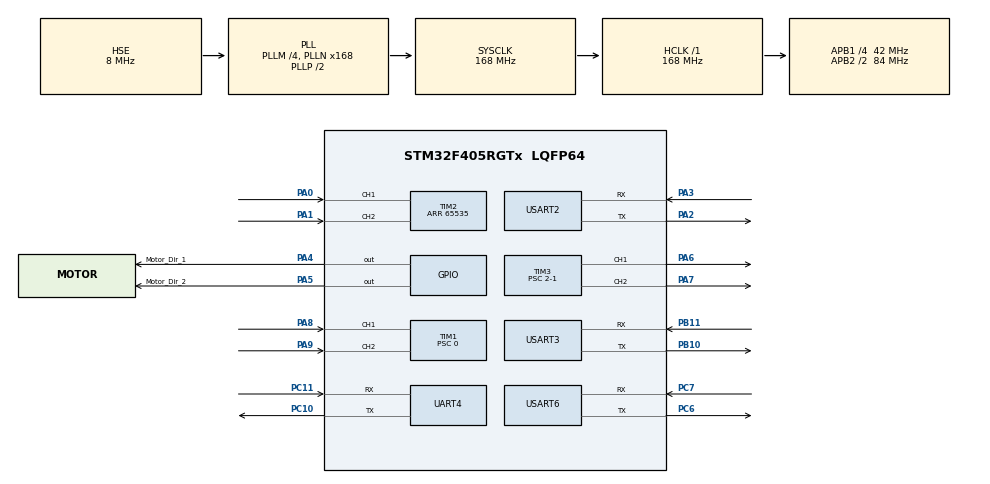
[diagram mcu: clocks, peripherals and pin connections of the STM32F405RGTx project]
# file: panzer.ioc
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Dma.Request0=USART3_RX
Dma.Request1=USART6_TX
Dma.Request2=USART6_RX
Dma.Request3=UART4_RX
Dma.Request4=UART4_TX
Dma.Request5=USART3_TX
Dma.Request6=USART2_RX
Dma.Request7=USART2_TX
Dma.UART4_RX.3.Direction=DMA_PERIPH_TO_MEMORY
Dma.UART4_RX.3.FIFOMode=DMA_FIFOMODE_DISABLE
Dma.UART4_RX.3.Instance=DMA1_Stream2
Dma.UART4_RX.3.MemDataAlignment=DMA_MDATAALIGN_BYTE
Dma.UART4_RX.3.MemInc=DMA_MINC_ENABLE
Dma.UART4_RX.3.Mode=DMA_CIRCULAR
Dma.UART4_RX.3.PeriphDataAlignment=DMA_PDATAALIGN_BYTE
Dma.UART4_RX.3.PeriphInc=DMA_PINC_DISABLE
Dma.UART4_RX.3.Priority=DMA_PRIORITY_LOW
Dma.UART4_TX.4.Direction=DMA_MEMORY_TO_PERIPH
Dma.UART4_TX.4.FIFOMode=DMA_FIFOMODE_DISABLE
Dma.UART4_TX.4.Instance=DMA1_Stream4
Dma.UART4_TX.4.MemDataAlignment=DMA_MDATAALIGN_BYTE
Dma.UART4_TX.4.MemInc=DMA_MINC_ENABLE
Dma.UART4_TX.4.Mode=DMA_NORMAL
Dma.UART4_TX.4.PeriphDataAlignment=DMA_PDATAALIGN_BYTE
Dma.UART4_TX.4.PeriphInc=DMA_PINC_DISABLE
Dma.UART4_TX.4.Priority=DMA_PRIORITY_LOW
Dma.USART2_RX.6.Direction=DMA_PERIPH_TO_MEMORY
Dma.USART2_RX.6.FIFOMode=DMA_FIFOMODE_DISABLE
Dma.USART2_RX.6.Instance=DMA1_Stream5
Dma.USART2_RX.6.MemDataAlignment=DMA_MDATAALIGN_BYTE
Dma.USART2_RX.6.MemInc=DMA_MINC_ENABLE
Dma.USART2_RX.6.Mode=DMA_CIRCULAR
Dma.USART2_RX.6.PeriphDataAlignment=DMA_PDATAALIGN_BYTE
Dma.USART2_RX.6.PeriphInc=DMA_PINC_DISABLE
Dma.USART2_RX.6.Priority=DMA_PRIORITY_LOW
Dma.USART2_TX.7.Direction=DMA_MEMORY_TO_PERIPH
Dma.USART2_TX.7.FIFOMode=DMA_FIFOMODE_DISABLE
Dma.USART2_TX.7.Instance=DMA1_Stream6
Dma.USART2_TX.7.MemDataAlignment=DMA_MDATAALIGN_BYTE
Dma.USART2_TX.7.MemInc=DMA_MINC_ENABLE
Dma.USART2_TX.7.Mode=DMA_NORMAL
Dma.USART2_TX.7.PeriphDataAlignment=DMA_PDATAALIGN_BYTE
Dma.USART2_TX.7.PeriphInc=DMA_PINC_DISABLE
Dma.USART2_TX.7.Priority=DMA_PRIORITY_LOW
Dma.USART3_RX.0.Direction=DMA_PERIPH_TO_MEMORY
Dma.USART3_RX.0.FIFOMode=DMA_FIFOMODE_DISABLE
Dma.USART3_RX.0.Instance=DMA1_Stream1
Dma.USART3_RX.0.MemDataAlignment=DMA_MDATAALIGN_BYTE
Dma.USART3_RX.0.MemInc=DMA_MINC_ENABLE
Dma.USART3_RX.0.Mode=DMA_CIRCULAR
Dma.USART3_RX.0.PeriphDataAlignment=DMA_PDATAALIGN_BYTE
Dma.USART3_RX.0.PeriphInc=DMA_PINC_DISABLE
Dma.USART3_RX.0.Priority=DMA_PRIORITY_LOW
Dma.USART3_TX.5.Direction=DMA_MEMORY_TO_PERIPH
Dma.USART3_TX.5.FIFOMode=DMA_FIFOMODE_DISABLE
Dma.USART3_TX.5.Instance=DMA1_Stream3
Dma.USART3_TX.5.MemDataAlignment=DMA_MDATAALIGN_BYTE
Dma.USART3_TX.5.MemInc=DMA_MINC_ENABLE
Dma.USART3_TX.5.Mode=DMA_NORMAL
Dma.USART3_TX.5.PeriphDataAlignment=DMA_PDATAALIGN_BYTE
Dma.USART3_TX.5.PeriphInc=DMA_PINC_DISABLE
Dma.USART3_TX.5.Priority=DMA_PRIORITY_LOW
Dma.USART6_RX.2.Direction=DMA_PERIPH_TO_MEMORY
Dma.USART6_RX.2.FIFOMode=DMA_FIFOMODE_DISABLE
Dma.USART6_RX.2.Instance=DMA2_Stream1
Dma.USART6_RX.2.MemDataAlignment=DMA_MDATAALIGN_BYTE
Dma.USART6_RX.2.MemInc=DMA_MINC_ENABLE
Dma.USART6_RX.2.Mode=DMA_CIRCULAR
Dma.USART6_RX.2.PeriphDataAlignment=DMA_PDATAALIGN_BYTE
Dma.USART6_RX.2.PeriphInc=DMA_PINC_DISABLE
Dma.USART6_RX.2.Priority=DMA_PRIORITY_LOW
Dma.USART6_TX.1.Direction=DMA_MEMORY_TO_PERIPH
Dma.USART6_TX.1.FIFOMode=DMA_FIFOMODE_DISABLE
Dma.USART6_TX.1.Instance=DMA2_Stream6
Dma.USART6_TX.1.MemDataAlignment=DMA_MDATAALIGN_BYTE
Dma.USART6_TX.1.MemInc=DMA_MINC_ENABLE
Dma.USART6_TX.1.Mode=DMA_NORMAL
Dma.USART6_TX.1.PeriphDataAlignment=DMA_PDATAALIGN_BYTE
Dma.USART6_TX.1.PeriphInc=DMA_PINC_DISABLE
Dma.USART6_TX.1.Priority=DMA_PRIORITY_LOW
Mcu.Family=STM32F4
Mcu.Name=STM32F405RGTx
Mcu.Package=LQFP64
NVIC.DMA1_Stream1_IRQn=true\:0\:0\:false\:false\:true\:false\:true\:true
NVIC.DMA1_Stream2_IRQn=true\:0\:0\:false\:false\:true\:false\:true\:true
NVIC.DMA1_Stream3_IRQn=true\:0\:0\:false\:false\:true\:false\:true\:true
NVIC.DMA1_Stream4_IRQn=true\:0\:0\:false\:false\:true\:false\:true\:true
NVIC.DMA1_Stream5_IRQn=true\:0\:0\:false\:false\:true\:false\:true\:true
NVIC.DMA1_Stream6_IRQn=true\:0\:0\:false\:false\:true\:false\:true\:true
NVIC.DMA2_Stream1_IRQn=true\:0\:0\:false\:false\:true\:false\:true\:true
NVIC.DMA2_Stream6_IRQn=true\:0\:0\:false\:false\:true\:false\:true\:true
NVIC.PriorityGroup=NVIC_PRIORITYGROUP_4
NVIC.TIM4_IRQn=true\:1\:0\:true\:false\:true\:true\:true\:true
NVIC.TIM5_IRQn=true\:2\:0\:true\:false\:true\:true\:true\:true
NVIC.UART4_IRQn=true\:0\:0\:true\:false\:true\:true\:true\:true
NVIC.USART2_IRQn=true\:0\:0\:true\:false\:true\:true\:true\:true
NVIC.USART3_IRQn=true\:0\:0\:false\:false\:true\:true\:true\:true
NVIC.USART6_IRQn=true\:0\:0\:true\:false\:true\:true\:true\:true
PA0-WKUP.GPIO_Speed=GPIO_SPEED_FREQ_VERY_HIGH
PA0-WKUP.Signal=S_TIM2_CH1_ETR
PA1.GPIO_Speed=GPIO_SPEED_FREQ_VERY_HIGH
PA1.Signal=S_TIM2_CH2
PA13.Mode=Serial_Wire
PA13.Signal=SYS_JTMS-SWDIO
PA14.Mode=Serial_Wire
PA14.Signal=SYS_JTCK-SWCLK
PA2.Mode=Asynchronous
PA2.Signal=USART2_TX
PA3.Mode=Asynchronous
PA3.Signal=USART2_RX
PA4.GPIO_Label=Motor_Dir_1
PA4.GPIO_PuPd=GPIO_PULLUP
PA4.PinState=GPIO_PIN_SET
PA4.Signal=GPIO_Output
PA5.GPIO_Label=Motor_Dir_2
PA5.GPIO_PuPd=GPIO_PULLUP
PA5.PinState=GPIO_PIN_SET
PA5.Signal=GPIO_Output
PA6.GPIO_Speed=GPIO_SPEED_FREQ_HIGH
PA6.Signal=S_TIM3_CH1
PA7.GPIO_Speed=GPIO_SPEED_FREQ_HIGH
PA7.Signal=S_TIM3_CH2
PA8.GPIO_PuPd=GPIO_PULLUP
PA8.GPIO_Speed=GPIO_SPEED_FREQ_VERY_HIGH
PA8.Signal=S_TIM1_CH1
PA9.GPIO_PuPd=GPIO_PULLUP
PA9.GPIO_Speed=GPIO_SPEED_FREQ_VERY_HIGH
PA9.Signal=S_TIM1_CH2
PB10.Mode=Asynchronous
PB10.Signal=USART3_TX
PB11.Mode=Asynchronous
PB11.Signal=USART3_RX
PC10.Mode=Asynchronous
PC10.Signal=UART4_TX
PC11.Mode=Asynchronous
PC11.Signal=UART4_RX
PC6.Mode=Asynchronous
PC6.Signal=USART6_TX
PC7.Mode=Asynchronous
PC7.Signal=USART6_RX
PH0-OSC_IN.Mode=HSE-External-Oscillator
PH0-OSC_IN.Signal=RCC_OSC_IN
PH1-OSC_OUT.Mode=HSE-External-Oscillator
PH1-OSC_OUT.Signal=RCC_OSC_OUT
ProjectManager.HeapSize=0x200
ProjectManager.StackSize=0x400
ProjectManager.TargetToolchain=MDK-ARM V5.32
RCC.48MHZClocksFreq_Value=84000000
RCC.AHBFreq_Value=168000000
RCC.APB1CLKDivider=RCC_HCLK_DIV4
RCC.APB1Freq_Value=42000000
RCC.APB1TimFreq_Value=84000000
RCC.APB2CLKDivider=RCC_HCLK_DIV2
RCC.APB2Freq_Value=84000000
RCC.APB2TimFreq_Value=168000000
RCC.CortexFreq_Value=168000000
RCC.HCLKFreq_Value=168000000
RCC.HSE_VALUE=8000000
RCC.HSI_VALUE=16000000
RCC.LSE_VALUE=32768
RCC.PLLM=4
RCC.PLLN=168
RCC.PLLSourceVirtual=RCC_PLLSOURCE_HSE
RCC.SYSCLKFreq_VALUE=168000000
RCC.SYSCLKSource=RCC_SYSCLKSOURCE_PLLCLK
RCC.VCOOutputFreq_Value=336000000
SH.S_TIM1_CH1.0=TIM1_CH1,Encoder_Interface
SH.S_TIM1_CH2.0=TIM1_CH2,Encoder_Interface
SH.S_TIM2_CH1_ETR.0=TIM2_CH1,Encoder_Interface
SH.S_TIM2_CH2.0=TIM2_CH2,Encoder_Interface
SH.S_TIM3_CH1.0=TIM3_CH1,PWM Generation1 CH1
SH.S_TIM3_CH2.0=TIM3_CH2,PWM Generation2 CH2
TIM1.AutoReloadPreload=TIM_AUTORELOAD_PRELOAD_ENABLE
TIM1.EncoderMode=TIM_ENCODERMODE_TI12
TIM1.Prescaler=0
TIM2.AutoReloadPreload=TIM_AUTORELOAD_PRELOAD_ENABLE
TIM2.EncoderMode=TIM_ENCODERMODE_TI12
TIM2.Period=65535
TIM3.AutoReloadPreload=TIM_AUTORELOAD_PRELOAD_ENABLE
TIM3.Channel-PWM\ Generation1\ CH1=TIM_CHANNEL_1
TIM3.Channel-PWM\ Generation2\ CH2=TIM_CHANNEL_2
TIM3.OCMode_PWM-PWM\ Generation1\ CH1=TIM_OCMODE_PWM2
TIM3.OCMode_PWM-PWM\ Generation2\ CH2=TIM_OCMODE_PWM2
TIM3.Period=1680-1
TIM3.Prescaler=2-1
TIM3.Pulse-PWM\ Generation1\ CH1=0
TIM3.Pulse-PWM\ Generation2\ CH2=0
TIM4.AutoReloadPreload=TIM_AUTORELOAD_PRELOAD_ENABLE
TIM4.Period=1000-1
TIM4.Prescaler=840-1
TIM5.AutoReloadPreload=TIM_AUTORELOAD_PRELOAD_ENABLE
TIM5.Period=10000-1
TIM5.Prescaler=840-1
UART4.VirtualMode=Asynchronous
USART2.VirtualMode=VM_ASYNC
USART3.VirtualMode=VM_ASYNC
USART6.VirtualMode=VM_ASYNC
VP_TIM3_VS_ClockSourceINT.Mode=Internal
VP_TIM4_VS_ClockSourceINT.Mode=Internal
VP_TIM5_VS_ClockSourceINT.Mode=Internal
board=custom

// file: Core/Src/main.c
/* USER CODE BEGIN Header */
/**
 ******************************************************************************
 * @file           : main.c
 * @brief          : Main program body
 ******************************************************************************
 * @attention
 *
 * Copyright (c) 2025 STMicroelectronics.
 * All rights reserved.
 *
 * This software is licensed under terms that can be found in the LICENSE file
 * in the root directory of this software component.
 * If no LICENSE file comes with this software, it is provided AS-IS.
 *
 ******************************************************************************
 */
/* USER CODE END Header */
#include "main.h"
#include "dma.h"
#include "tim.h"
#include "usart.h"
#include "gpio.h"

/* USER CODE BEGIN Includes */
#include "Encode.h"
#include "interurp.h"
#include "Bule_Tooch.h"
#include "stdint.h"

/* USER CODE END Includes */

void SystemClock_Config(void);

int main(void)
{

  /* MCU Configuration--------------------------------------------------------*/

  /* Reset of all peripherals, Initializes the Flash interface and the Systick. */
  HAL_Init();

  /* Configure the system clock */
  SystemClock_Config();

  /* Initialize all configured peripherals */
  MX_GPIO_Init();
  MX_DMA_Init();
  MX_TIM1_Init();
  MX_TIM2_Init();
  MX_TIM3_Init();
  MX_TIM4_Init();
  MX_USART2_UART_Init();
  MX_USART3_UART_Init();
  MX_UART4_Init();
  MX_USART6_UART_Init();
  MX_TIM5_Init();
  /* USER CODE BEGIN 2 */

  UART_Task_Init();
  Bule_Tooch_UART2_DMA_Start();
  Yaw_pid_Init();
  Motor_Init();

  //	Usart3_send_HWT101_Zero();

  ResetHWT101();
  HAL_Delay(2000);
  HAL_TIM_Base_Start_IT(&GAP_TIM);
  HAL_TIM_Base_Start_IT(&htim5);
  HAL_GPIO_WritePin(GPIOC, GPIO_PIN_13, GPIO_PIN_SET);

  /* USER CODE END 2 */

  /* Infinite loop */
  while (1)
  {

  }
}

void SystemClock_Config(void)
{
  RCC_OscInitTypeDef RCC_OscInitStruct = {0};
  RCC_ClkInitTypeDef RCC_ClkInitStruct = {0};

  /** Configure the main internal regulator output voltage
  */
  __HAL_RCC_PWR_CLK_ENABLE();
  __HAL_PWR_VOLTAGESCALING_CONFIG(PWR_REGULATOR_VOLTAGE_SCALE1);

  /** Initializes the RCC Oscillators according to the specified parameters
  * in the RCC_OscInitTypeDef structure.
  */
  RCC_OscInitStruct.OscillatorType = RCC_OSCILLATORTYPE_HSE;
  RCC_OscInitStruct.HSEState = RCC_HSE_ON;
  RCC_OscInitStruct.PLL.PLLState = RCC_PLL_ON;
  RCC_OscInitStruct.PLL.PLLSource = RCC_PLLSOURCE_HSE;
  RCC_OscInitStruct.PLL.PLLM = 4;
  RCC_OscInitStruct.PLL.PLLN = 168;
  RCC_OscInitStruct.PLL.PLLP = RCC_PLLP_DIV2;
  RCC_OscInitStruct.PLL.PLLQ = 4;
  if (HAL_RCC_OscConfig(&RCC_OscInitStruct) != HAL_OK)
  {
    Error_Handler();
  }

  /** Initializes the CPU, AHB and APB buses clocks
  */
  RCC_ClkInitStruct.ClockType = RCC_CLOCKTYPE_HCLK|RCC_CLOCKTYPE_SYSCLK
                              |RCC_CLOCKTYPE_PCLK1|RCC_CLOCKTYPE_PCLK2;
  RCC_ClkInitStruct.SYSCLKSource = RCC_SYSCLKSOURCE_PLLCLK;
  RCC_ClkInitStruct.AHBCLKDivider = RCC_SYSCLK_DIV1;
  RCC_ClkInitStruct.APB1CLKDivider = RCC_HCLK_DIV4;
  RCC_ClkInitStruct.APB2CLKDivider = RCC_HCLK_DIV2;

  if (HAL_RCC_ClockConfig(&RCC_ClkInitStruct, FLASH_LATENCY_5) != HAL_OK)
  {
    Error_Handler();
  }
}

void Error_Handler(void)
{
  __disable_irq();
  while (1)
  {
  }
}
